# STM32WBAxx register map
File version: 0.2
Registers are 32-bit, read-write, reset 0x0 unless marked. A register's access mark holds for its fields unless they carry their own. Offsets are from the block's base; lines under a group give offsets from that group; [hi:lo] are bit positions; {n}, {i} and the like mark numbered series; 'fields as' and 'values as' point back to an identical list; <NAME> marks a mode.

## Memory map
0x40002C00 WWDG size 0x400 — System window watchdog
0x40003000 IWDG size 0x400 — Independent watchdog
0x40005400 I2C1 size 0x400 — Inter-integrated circuit
0x40020000 GPDMA size 0x1000 — General purpose direct memory access controller
0x40023000 CRC size 0x400 — Cyclic redundancy check calculation unit
0x40032400 GTZC1_TZSC size 0x400
0x40032800 GTZC1_TZIC size 0x400
0x40032C00 GTZC1_MPCBB1 size 0x400 — GTZC1_MPCBB1 address block description
0x40033000 GTZC1_MPCBB2 size 0x400
0x40034000 GTZC1_MPCBB6 size 0x400 — GTZC1_MPCBB6 address block description
0x42020000 GPIOA size 0x400 — General-purpose I/Os
0x42020400 GPIOB size 0x400 — General-purpose I/Os
0x42020800 GPIOC size 0x400 — General-purpose I/Os
0x42021C00 GPIOH size 0x400 — General-purpose I/Os
0x420C0400 HASH size 0x400 — Hash processor
0x420C0800 RNG size 0x400 — Random number generator
0x420C1C00 HSEM size 0x400 — Hardware semaphore
0x420C2000 PKA size 0x2000 — Private key accelerator
0x46002800 I2C3 size 0x400
0x46022000 EXTI size 0x400 — External interrupt/event controller
0x50002C00 SEC_WWDG size 0x400
0x50003000 SEC_IWDG size 0x400
0x50005400 SEC_I2C1 size 0x400
0x50020000 SEC_GPDMA size 0x1000
0x50023000 SEC_CRC size 0x400
0x50032400 SEC_GTZC1_TZSC size 0x400
0x50032800 SEC_GTZC1_TZIC size 0x400
0x50032C00 SEC_GTZC1_MPCBB1 size 0x400
0x50033000 SEC_GTZC1_MPCBB2 size 0x400
0x50034000 SEC_GTZC1_MPCBB6 size 0x400
0x52020000 SEC_GPIOA size 0x400
0x52020400 SEC_GPIOB size 0x400
0x52020800 SEC_GPIOC size 0x400
0x52021C00 SEC_GPIOH size 0x400
0x520C0400 SEC_HASH size 0x400
0x520C0800 SEC_RNG size 0x400
0x520C1C00 SEC_HSEM size 0x400
0x520C2000 SEC_PKA size 0x2000
0x56002800 SEC_I2C3 size 0x400
0x56022000 SEC_EXTI size 0x400

## Interrupts
0 WWDG — Window Watchdog interrupt
1 PDV (EXTI) — Power voltage monitor
{n+11} EXTI{n} (EXTI) (n=0..15) — EXTI line{n} interrupt
{n+29} GPDMA1_CH{n} (GPDMA) (n=0..7) — GPDMA1 channel {n} global interrupt
43 I2C1_EV (I2C1) — I2C1 event interrupt
44 I2C1_ER (I2C1) — I2C1 error interrupt
54 I2C3_EV (I2C3) — I2C3 event interrupt
55 I2C3_ER (I2C3) — I2C3 error interrupt
59 RNG — RNG global interrupt
61 HASH — HASH interrupt
62 PKA — PKA global interrupt
68 HSEM — HSEM non-secure interrupt
69 HSEM_S (HSEM) — HSEM secure interrupt

## CRC — Cyclic redundancy check calculation unit
Base 0x40023000
Same registers: SEC_CRC 0x50023000
0x00 CRC_DR reset 0xFFFFFFFF — CRC data register
  [31:0] DR — Data register bits This register is used to write new data to the CRC calculator. It holds the previous CRC calculation result when it is read. If the data size is less than 32 bits, the least significant bits are used to write/read the correct value.
0x04 CRC_IDR — CRC independent data register
  [31:0] IDR — General-purpose 32-bit data register bits These bits can be used as a temporary storage location for four bytes. This register is not affected by CRC resets generated by the RESET bit in the CRC_CR register
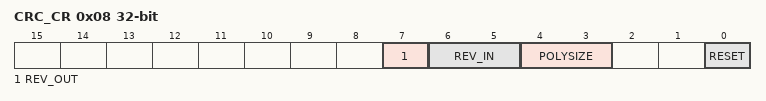
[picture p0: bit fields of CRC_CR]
0x08 CRC_CR — CRC control register
  [7] REV_OUT — Reverse output data This bit controls the reversal of the bit order of the output data.
    0=Bit order not affected; 1=Bit-reversed output format
  [6:5] REV_IN — Reverse input data These bits control the reversal of the bit order of the input data
    0=Bit order not affected; 1=Bit reversal done by byte; 2=Bit reversal done by half-word; 3=Bit reversal done by word
  [4:3] POLYSIZE — Polynomial size These bits control the size of the polynomial.
    0=32 bit polynomial; 1=16 bit polynomial; 2=8 bit polynomial; 3=7 bit polynomial
  [0] RESET — RESET bit This bit is set by software to reset the CRC calculation unit and set the data register to the value stored in the CRC_INIT register. This bit can only be set, it is automatically cleared by hardware
0x10 CRC_INIT reset 0xFFFFFFFF — CRC initial value
  [31:0] CRC_INIT — Programmable initial CRC value This register is used to write the CRC initial value.
0x14 CRC_POL reset 0x4C11DB7 — CRC polynomial
  [31:0] POL — Programmable polynomial This register is used to write the coefficients of the polynomial to be used for CRC calculation. If the polynomial size is less than 32 bits, the least significant bits have to be used to program the correct value.

## Notices in the file
Copyright (c) 2022 STMicroelectronics.
SPDX-License-Identifier: Apache-2.0
Licensed under the Apache License, Version 2.0 (the "License");
you may not use this file except in compliance with the License.
You may obtain a copy of the License at
http://www.apache.org/licenses/LICENSE-2.0
Unless required by applicable law or agreed to in writing, software
distributed under the License is distributed on an "AS IS" BASIS,
WITHOUT WARRANTIES OR CONDITIONS OF ANY KIND, either express or implied.
See the License for the specific language governing permissions and
limitations under the License.
